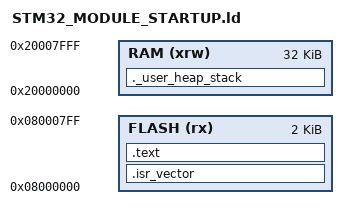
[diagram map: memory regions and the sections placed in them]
/*
******************************************************************************
**

**  File        : STM32_MODULE_STARTUP.ld
**
**  Abstract    : Linker script for most STM32 M4 series MCU to populate one
**                page of flash memory with a startup application
**
**  Target      : STMicroelectronics STM32
**
**  Distribution: The file is distributed “as is,” without any warranty
**                of any kind.
**
*****************************************************************************
** @attention
**
** <h2><center>&copy; COPYRIGHT(c) 2019 STMicroelectronics</center></h2>
**
** Redistribution and use in source and binary forms, with or without modification,
** are permitted provided that the following conditions are met:
**   1. Redistributions of source code must retain the above copyright notice,
**      this list of conditions and the following disclaimer.
**   2. Redistributions in binary form must reproduce the above copyright notice,
**      this list of conditions and the following disclaimer in the documentation
**      and/or other materials provided with the distribution.
**   3. Neither the name of STMicroelectronics nor the names of its contributors
**      may be used to endorse or promote products derived from this software
**      without specific prior written permission.
**
** THIS SOFTWARE IS PROVIDED BY THE COPYRIGHT HOLDERS AND CONTRIBUTORS "AS IS"
** AND ANY EXPRESS OR IMPLIED WARRANTIES, INCLUDING, BUT NOT LIMITED TO, THE
** IMPLIED WARRANTIES OF MERCHANTABILITY AND FITNESS FOR A PARTICULAR PURPOSE ARE
** DISCLAIMED. IN NO EVENT SHALL THE COPYRIGHT HOLDER OR CONTRIBUTORS BE LIABLE
** FOR ANY DIRECT, INDIRECT, INCIDENTAL, SPECIAL, EXEMPLARY, OR CONSEQUENTIAL
** DAMAGES (INCLUDING, BUT NOT LIMITED TO, PROCUREMENT OF SUBSTITUTE GOODS OR
** SERVICES; LOSS OF USE, DATA, OR PROFITS; OR BUSINESS INTERRUPTION) HOWEVER
** CAUSED AND ON ANY THEORY OF LIABILITY, WHETHER IN CONTRACT, STRICT LIABILITY,
** OR TORT (INCLUDING NEGLIGENCE OR OTHERWISE) ARISING IN ANY WAY OUT OF THE USE
** OF THIS SOFTWARE, EVEN IF ADVISED OF THE POSSIBILITY OF SUCH DAMAGE.
**
*****************************************************************************
*/

/* Entry Point */
ENTRY(Reset_Handler)

/* Highest address of the user mode stack */
_estack = ORIGIN(RAM) + LENGTH(RAM);	/* end of "RAM" Ram type memory */
__stack = _estack;
/* Generate a link error if heap and stack don't fit into RAM */
_Min_Heap_Size = 0;	/* required amount of heap  */
_Min_Stack_Size = 0;	/* required amount of stack */
/* Starting address of flash region.*/
_flash_start = 0x8000000;
/* User application start.*/
_user_app_offset = 0x800;
_user_app_start = _flash_start + _user_app_offset + 0x4;
/* Bootloader memory address.*/
_sysmem_start = 0x1FFF0000;
_bootloader_start = _sysmem_start + 0x4;

/* Specify the memory areas */
MEMORY
{
    /* Less than the actual ram of any of the target MCU, but more
     * than enough for this application.
     */
    RAM (xrw)      : ORIGIN = 0x20000000, LENGTH = 32K 
    /* Only the first page is populated.*/
    FLASH (rx)     : ORIGIN = _flash_start,  LENGTH = _user_app_offset
}

/* Define output sections */
SECTIONS
{
  /* The startup code goes first into FLASH */
  .isr_vector :
  {
    . = ALIGN(4);
    KEEP(*(.isr_vector)) /* Startup code */
    . = ALIGN(4);
  } >FLASH

  /* The program code and other data goes into FLASH */
  .text :
  {
    . = ALIGN(4);
    *(.text)           /* .text sections (code) */
    *(.text*)          /* .text* sections (code) */
    . = ALIGN(4);
    _etext = .;        /* define a global symbols at end of code */
  } >FLASH

  /* User_heap_stack section, used to check that there is enough RAM left */
  ._user_heap_stack :
  {
    . = ALIGN(8);
    PROVIDE ( end = . );
    PROVIDE ( _end = . );
    . = . + _Min_Heap_Size;
    . = . + _Min_Stack_Size;
    . = ALIGN(8);
  } >RAM

  .ARM.attributes 0 : { *(.ARM.attributes) }
}


